# MDR_MLDR155 register map
Vendor: Milandr; Series: ARMCM4; File version: 2.0
CPU: CM4 r0p0, little endian, MPU, FPU, 3 interrupt priority bits
Registers are 32-bit, read-write, reset 0x0 unless marked. A register's access mark holds for its fields unless they carry their own. Offsets are from the block's base; [hi:lo] are bit positions; {n}, {i} and the like mark numbered series; 'fields as' and 'values as' point back to an identical list.

## MDR_RST_CLOCK — CLock Control
Base 0x40000000
0x00 KEY — Clock Unlock Register
  [31:0] Value — Reg value
0x04 MAX_CLK — MAX_CLK Select Register
  [3:0] Select — Select MAX_CLOCK source
    0=HSI (MAX_CLOCK is HSI); 1=HSI_div2 (MAX_CLOCK is HSI/2); 2=HSE0 (MAX_CLOCK is HSE0); 3=HSE0_div2 (MAX_CLOCK is HSE0/2); 4=HSE1 (MAX_CLOCK is HSE1); 5=HSE1_div2 (MAX_CLOCK is HSE1/2); 6=LSI (MAX_CLOCK is LSI); 7=LSE (MAX_CLOCK is LSE); {v}=PLL{v-8} (MAX_CLOCK is PLL{v-8}) (v=8..11)
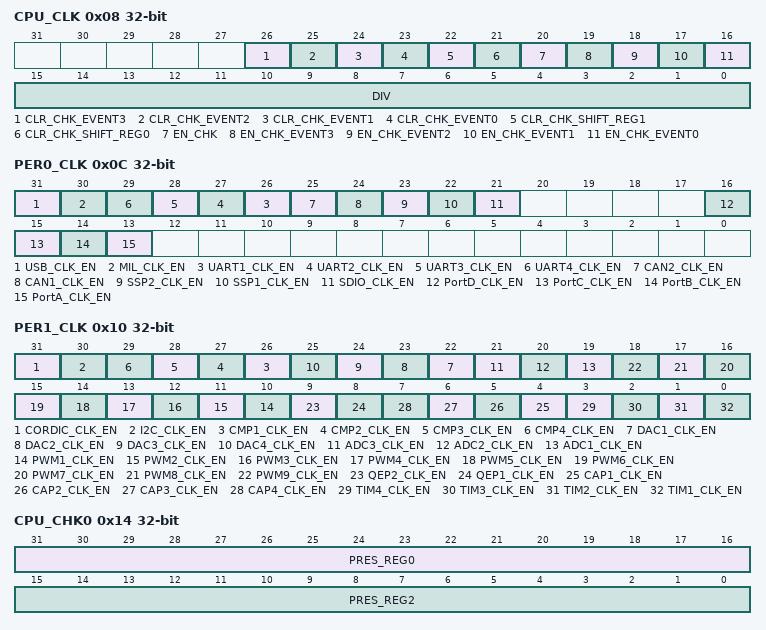
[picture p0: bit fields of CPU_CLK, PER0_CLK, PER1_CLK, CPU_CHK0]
0x08 CPU_CLK
  [26] CLR_CHK_EVENT3 — Clear highest freq event
    0=Inactive (No action); 1=Clear level
  [25] CLR_CHK_EVENT2 — Clear high freq event
    0=Inactive (No action); 1=Clear level
  [24] CLR_CHK_EVENT1 — Clear low freq event
    0=Inactive (No action); 1=Clear level
  [23] CLR_CHK_EVENT0 — Clear no freq event
    0=Inactive (No action); 1=Clear level
  [22] CLR_CHK_SHIFT_REG1 — Clear Max Freq level
    0=Inactive (No action); 1=Clear level
  [21] CLR_CHK_SHIFT_REG0 — Clear Min Freq level
    0=Inactive (No action); 1=Clear level
  [20] EN_CHK — Clock Checker enable
    0=Off (Disable); 1=On (Enable)
  [19] EN_CHK_EVENT3 — Go to HSI if active clock is Highest
    0=Off (Disable); 1=On (Enable)
  [18] EN_CHK_EVENT2 — Go to HSI if active clock is High
    0=Off (Disable); 1=On (Enable)
  [17] EN_CHK_EVENT1 — Go to HSI if active clock is low
    0=Off (Disable); 1=On (Enable)
  [16] EN_CHK_EVENT0 — Go to HSI on lose active clock
    0=Off (Disable); 1=On (Enable)
  [15:0] DIV — CPU_CLock div from MAX_CLOCK
0x0C PER0_CLK — Periph0 Clock Enable Register
  [all] fields
    0=Off (Disable); 1=On (Enable)
  [31] USB_CLK_EN — USB Clock Enable
  [30] MIL_CLK_EN — MIL Clock Enable
  [n+25] UART{n}_CLK_EN (n=1..4) — UART{n} Clock Enable
  [25] CAN2_CLK_EN — CAN2 Clock Enable
  [24] CAN1_CLK_EN — CAN1 Clock Enable
  [23] SSP2_CLK_EN — SSP2 Clock Enable
  [22] SSP1_CLK_EN — SSP1 Clock Enable
  [21] SDIO_CLK_EN — SDIO Clock Enable
  [16] PortD_CLK_EN — GPIO Port Clock Enable
  [15] PortC_CLK_EN — GPIO Port Clock Enable
  [14] PortB_CLK_EN — GPIO Port Clock Enable
  [13] PortA_CLK_EN — GPIO Port Clock Enable
0x10 PER1_CLK — Periph1 Clock Enable Register
  [all] fields
    0=Off (Disable); 1=On (Enable)
  [31] CORDIC_CLK_EN — CORDIC Clock Enable
  [30] I2C_CLK_EN — I2C Clock Enable
  [n+25] CMP{n}_CLK_EN (n=1..4) — Comparator{n} Clock Enable
  [n+21] DAC{n}_CLK_EN (n=1..4) — DAC{n} Clock Enable
  [21] ADC3_CLK_EN — ADC3 Clock Enable
  [20] ADC2_CLK_EN — ADC2 Clock Enable
  [19] ADC1_CLK_EN — ADC1 Clock Enable
  [n+9] PWM{n}_CLK_EN (n=1..9) — PWM{n} Clock Enable
  [9] QEP2_CLK_EN — Encoder2 Clock Enable
  [8] QEP1_CLK_EN — Encoder1 Clock Enable
  [n+3] CAP{n}_CLK_EN (n=1..4) — Capture{n} Clock Enable
  [3] TIM4_CLK_EN — Timer4 Clock Enable
  [2] TIM3_CLK_EN — Timer3 Clock Enable
  [1] TIM2_CLK_EN — Timer1 Clock Enable
  [0] TIM1_CLK_EN — Timer1 Clock Enable
0x14 CPU_CHK0 — Clock Checker Register
  [31:16] PRES_REG0 — FreqRef Prescaller for Fast
  [15:0] PRES_REG2 — FreqRef Prescaller for Slow
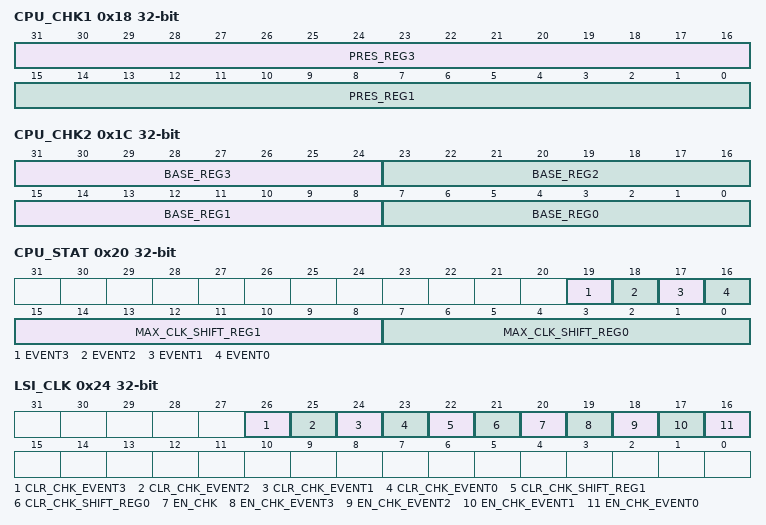
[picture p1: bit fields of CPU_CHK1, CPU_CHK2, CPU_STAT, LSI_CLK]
0x18 CPU_CHK1 — Clock Checker Register
  [31:16] PRES_REG3 — Clock Prescaller for Slow
  [15:0] PRES_REG1 — Clock Prescaller for Fast
0x1C CPU_CHK2 — Clock Checker Register
  [31:24] BASE_REG3 — Max factor for FASTEST
  [23:16] BASE_REG2 — Max factor for FAST
  [15:8] BASE_REG1 — Min factor for SLOW
  [7:0] BASE_REG0 — Min factor for SLOWEST
0x20 CPU_STAT — Clock Status Register
  [19] EVENT3 — Event FASTEST
    0=Off (Inactive); 1=On (Active)
  [18] EVENT2 — Event FAST
    0=Off (Inactive); 1=On (Active)
  [17] EVENT1 — Event SLOW
    0=Off (Inactive); 1=On (Active)
  [16] EVENT0 — Event SLOWEST
    0=Off (Inactive); 1=On (Active)
  [15:8] MAX_CLK_SHIFT_REG1 — Max factor detected for FAST
  [7:0] MAX_CLK_SHIFT_REG0 — Max factor detected for SLOW
0x24 LSI_CLK — Clock Contorl Register
  [26] CLR_CHK_EVENT3 — Clear highest freq event
    0=Inactive (No action); 1=Clear level
  [25] CLR_CHK_EVENT2 — Clear high freq event
    0=Inactive (No action); 1=Clear level
  [24] CLR_CHK_EVENT1 — Clear low freq event
    0=Inactive (No action); 1=Clear level
  [23] CLR_CHK_EVENT0 — Clear no freq event
    0=Inactive (No action); 1=Clear level
  [22] CLR_CHK_SHIFT_REG1 — Clear Max Freq level
    0=Inactive (No action); 1=Clear level
  [21] CLR_CHK_SHIFT_REG0 — Clear Min Freq level
    0=Inactive (No action); 1=Clear level
  [20] EN_CHK — Clock Checker enable
    0=Off (Disable); 1=On (Enable)
  [19] EN_CHK_EVENT3 — Go to HSI if active clock is Highest
    0=Off (Disable); 1=On (Enable)
  [18] EN_CHK_EVENT2 — Go to HSI if active clock is High
    0=Off (Disable); 1=On (Enable)
  [17] EN_CHK_EVENT1 — Go to HSI if active clock is low
    0=Off (Disable); 1=On (Enable)
  [16] EN_CHK_EVENT0 — Go to HSI on lose active clock
    0=Off (Disable); 1=On (Enable)
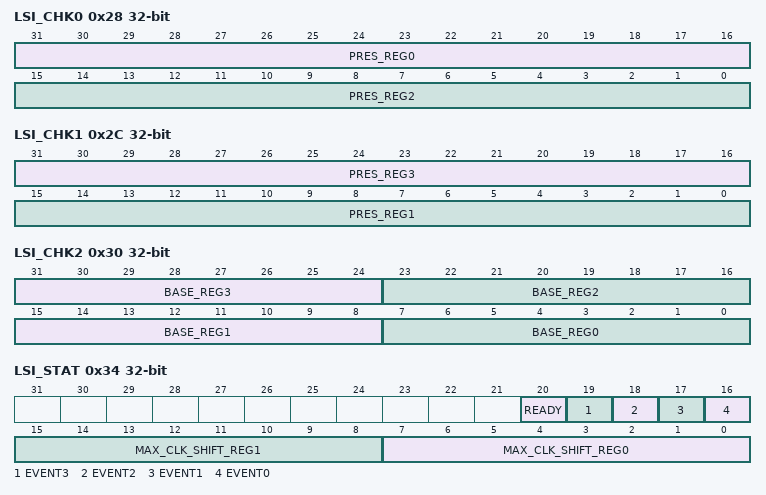
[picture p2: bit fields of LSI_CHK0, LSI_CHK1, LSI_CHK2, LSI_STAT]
0x28 LSI_CHK0 — Clock Checker Register
  fields as CPU_CHK0
0x2C LSI_CHK1 — Clock Checker Register
  fields as CPU_CHK1
0x30 LSI_CHK2 — Clock Checker Register
  fields as CPU_CHK2
0x34 LSI_STAT (reset mask 0xFFFFF) — Clock Status Register
  [20] READY — Clock Ready
    0=Off (Clock not Ready); 1=On (Clock Ready)
  [19] EVENT3 — Event FASTEST
    0=Off (Inactive); 1=On (Active)
  [18] EVENT2 — Event FAST
    0=Off (Inactive); 1=On (Active)
  [17] EVENT1 — Event SLOW
    0=Off (Inactive); 1=On (Active)
  [16] EVENT0 — Event SLOWEST
    0=Off (Inactive); 1=On (Active)
  [15:8] MAX_CLK_SHIFT_REG1 — Max factor detected for FAST
  [7:0] MAX_CLK_SHIFT_REG0 — Max factor detected for SLOW
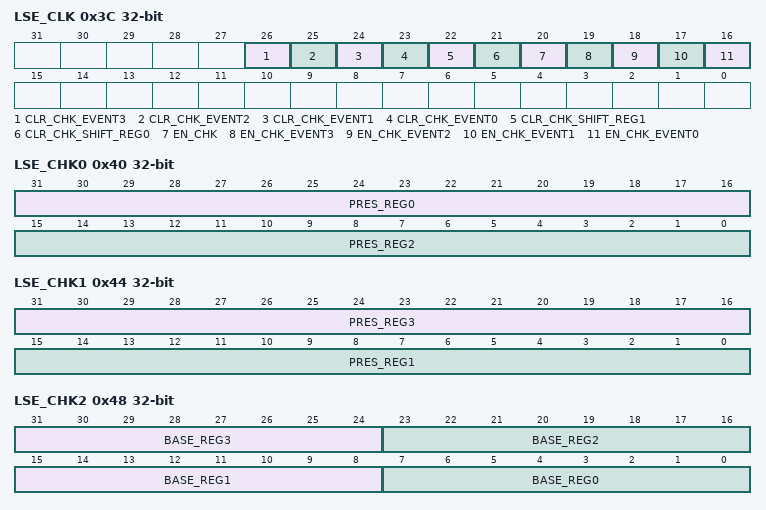
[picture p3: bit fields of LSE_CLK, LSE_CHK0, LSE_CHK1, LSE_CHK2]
0x3C LSE_CLK — Clock Contorl Register
  fields as LSI_CLK
0x40 LSE_CHK0 — Clock Checker Register
  fields as CPU_CHK0
0x44 LSE_CHK1 — Clock Checker Register
  fields as CPU_CHK1
0x48 LSE_CHK2 — Clock Checker Register
  fields as CPU_CHK2
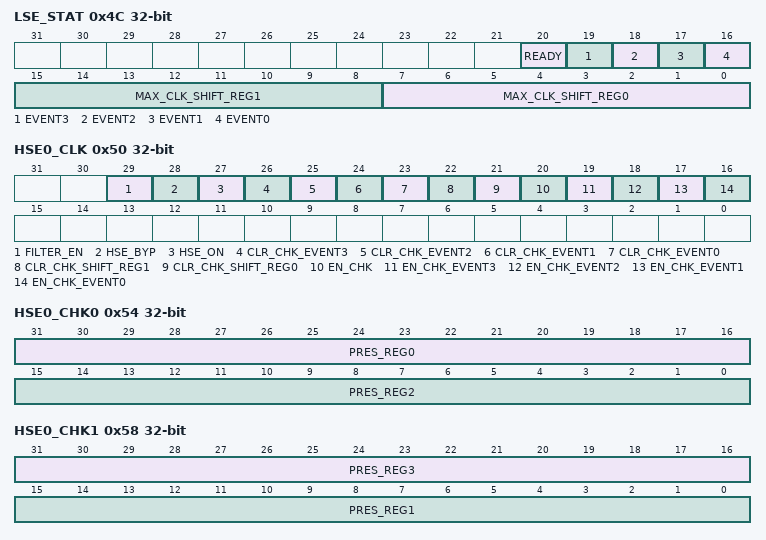
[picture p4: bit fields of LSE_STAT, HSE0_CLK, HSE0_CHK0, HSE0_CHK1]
0x4C LSE_STAT (reset mask 0xFFFFF) — Clock Status Register
  fields as LSI_STAT
0x50 HSE0_CLK (reset mask 0x7FF0000) — Clock Contorl Register
  [29] FILTER_EN — Filter Enable
    0=Off (Disable); 1=On (Enable)
  [28] HSE_BYP — ByPass Mode
    0=Off (Disable); 1=On (Enable)
  [27] HSE_ON — Generator Enable
    0=Off (Disable); 1=On (Enable)
  [26] CLR_CHK_EVENT3 — Clear highest freq event
    0=Inactive (No action); 1=Clear level
  [25] CLR_CHK_EVENT2 — Clear high freq event
    0=Inactive (No action); 1=Clear level
  [24] CLR_CHK_EVENT1 — Clear low freq event
    0=Inactive (No action); 1=Clear level
  [23] CLR_CHK_EVENT0 — Clear no freq event
    0=Inactive (No action); 1=Clear level
  [22] CLR_CHK_SHIFT_REG1 — Clear Max Freq level
    0=Inactive (No action); 1=Clear level
  [21] CLR_CHK_SHIFT_REG0 — Clear Min Freq level
    0=Inactive (No action); 1=Clear level
  [20] EN_CHK — Clock Checker enable
    0=Off (Disable); 1=On (Enable)
  [19] EN_CHK_EVENT3 — Go to HSI if active clock is Highest
    0=Off (Disable); 1=On (Enable)
  [18] EN_CHK_EVENT2 — Go to HSI if active clock is High
    0=Off (Disable); 1=On (Enable)
  [17] EN_CHK_EVENT1 — Go to HSI if active clock is low
    0=Off (Disable); 1=On (Enable)
  [16] EN_CHK_EVENT0 — Go to HSI on lose active clock
    0=Off (Disable); 1=On (Enable)
0x54 HSE0_CHK0 — Clock Checker Register
  fields as CPU_CHK0
0x58 HSE0_CHK1 — Clock Checker Register
  fields as CPU_CHK1
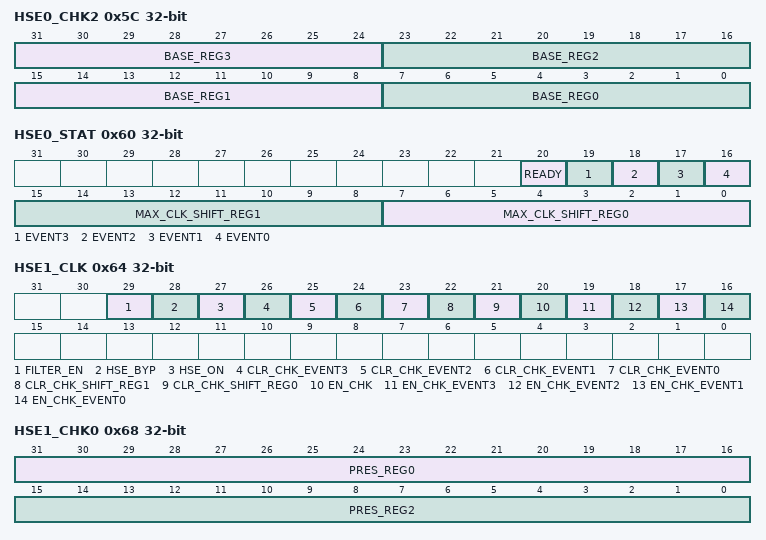
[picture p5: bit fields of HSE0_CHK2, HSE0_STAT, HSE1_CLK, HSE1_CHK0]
0x5C HSE0_CHK2 — Clock Checker Register
  fields as CPU_CHK2
0x60 HSE0_STAT (reset mask 0xFFFFF) — Clock Status Register
  fields as LSI_STAT
0x64 HSE1_CLK (reset mask 0x7FF0000) — Clock Contorl Register
  fields as HSE0_CLK
0x68 HSE1_CHK0 — Clock Checker Register
  fields as CPU_CHK0
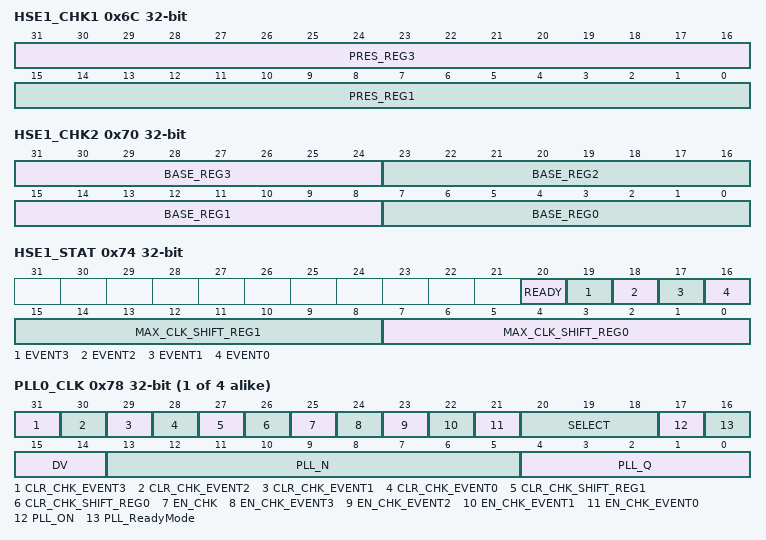
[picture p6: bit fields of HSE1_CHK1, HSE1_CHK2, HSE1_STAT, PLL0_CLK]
0x6C HSE1_CHK1 — Clock Checker Register
  fields as CPU_CHK1
0x70 HSE1_CHK2 — Clock Checker Register
  fields as CPU_CHK2
0x74 HSE1_STAT (reset mask 0xFFFFF) — Clock Status Register
  fields as LSI_STAT
{0x78+0x14*i} PLL{i}_CLK (i=0..3) — PLL0 Control
  [31] CLR_CHK_EVENT3 — Clear highest freq event
    0=Inactive (No action); 1=Clear level
  [30] CLR_CHK_EVENT2 — Clear high freq event
    0=Inactive (No action); 1=Clear level
  [29] CLR_CHK_EVENT1 — Clear low freq event
    0=Inactive (No action); 1=Clear level
  [28] CLR_CHK_EVENT0 — Clear no freq event
    0=Inactive (No action); 1=Clear level
  [27] CLR_CHK_SHIFT_REG1 — Clear Max Freq level
    0=Inactive (No action); 1=Clear level
  [26] CLR_CHK_SHIFT_REG0 — Clear Min Freq level
    0=Inactive (No action); 1=Clear level
  [25] EN_CHK — Clock Checker enable
    0=Off (Disable); 1=On (Enable)
  [24] EN_CHK_EVENT3 — Go to HSI if active clock is Highest
    0=Off (Disable); 1=On (Enable)
  [23] EN_CHK_EVENT2 — Go to HSI if active clock is High
    0=Off (Disable); 1=On (Enable)
  [22] EN_CHK_EVENT1 — Go to HSI if active clock is low
    0=Off (Disable); 1=On (Enable)
  [21] EN_CHK_EVENT0 — Go to HSI on lose active clock
    0=Off (Disable); 1=On (Enable)
  [20:18] SELECT — Select PLL Input
    0=HSI (HSI signal); 1=HSI_div2 (HSI/2 signal); 2=HSE0 (HSE0 signal); 3=HSE0_div2 (HSE0/2 signal); 4=HSE1 (HSE1 signal); 5=HSE1_div2 (HSE1/2 signal)
  [17] PLL_ON — PLL Enable
    0=Off (Disable); 1=On (Enable)
  [16] PLL_ReadyMode — Enable output after ready only
    0=Off (Disable); 1=On (Enable)
  [15:14] DV — PLL Output Divider
    0=div1 (Divider); 1=div2 (Divider); 2=div4 (Divider); 3=div8 (Divider)
  [13:5] PLL_N — PLL Freq multiplier
  [4:0] PLL_Q — PLL Freq divider
    {v}=div{v+1} (Divider) (v=0..31)
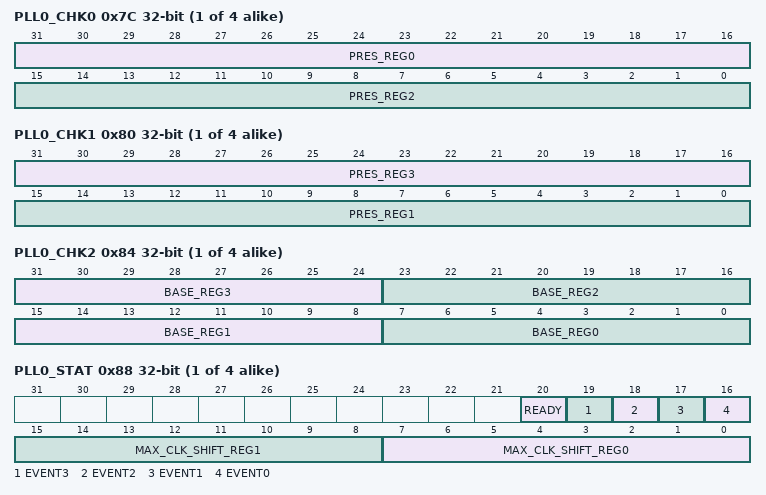
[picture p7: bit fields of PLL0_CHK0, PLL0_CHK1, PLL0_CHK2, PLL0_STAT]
{0x7C+0x14*i} PLL{i}_CHK0 (i=0..3) — Clock Checker Register
  fields as CPU_CHK0
{0x80+0x14*i} PLL{i}_CHK1 (i=0..3) — Clock Checker Register
  fields as CPU_CHK1
{0x84+0x14*i} PLL{i}_CHK2 (i=0..3) — Clock Checker Register
  fields as CPU_CHK2
{0x88+0x14*i} PLL{i}_STAT (reset mask 0xFFFFF) (i=0..3) — Clock Status Register
  fields as LSI_STAT
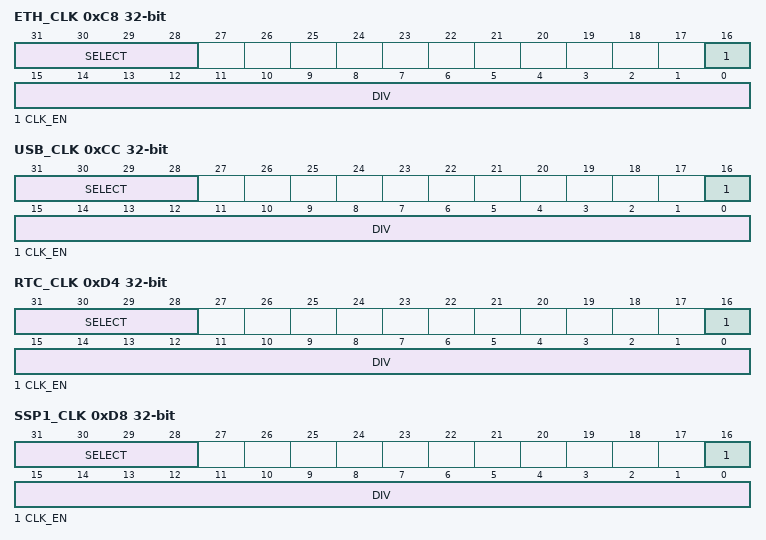
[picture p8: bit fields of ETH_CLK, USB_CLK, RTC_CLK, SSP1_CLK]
0xC8 ETH_CLK (reset mask 0xF001FFF) — Async Clock Control
  [31:28] SELECT — PeriphClock Enable
    0=HSI (Clock Source); 1=HSE0 (Clock Source); 2=HSE1 (Clock Source); 3=LSI (Clock Source); 4=LSE (Clock Source); 5=PLL0 (Clock Source); 6=PLL1 (Clock Source); 7=PLL2 (Clock Source); 13=MAX_CLK (Clock Source)
  [16] CLK_EN — PeriphClock Enable
    0=Off (Clock Off); 1=On (Clock On)
  [15:0] DIV — Div to PeriphClock
0xCC USB_CLK (reset mask 0xF001FFF) — Async Clock Control
  fields as ETH_CLK
0xD4 RTC_CLK (reset mask 0xF001FFF) — Async Clock Control
  fields as ETH_CLK
0xD8 SSP1_CLK (reset mask 0xF001FFF) — Async Clock Control
  fields as ETH_CLK
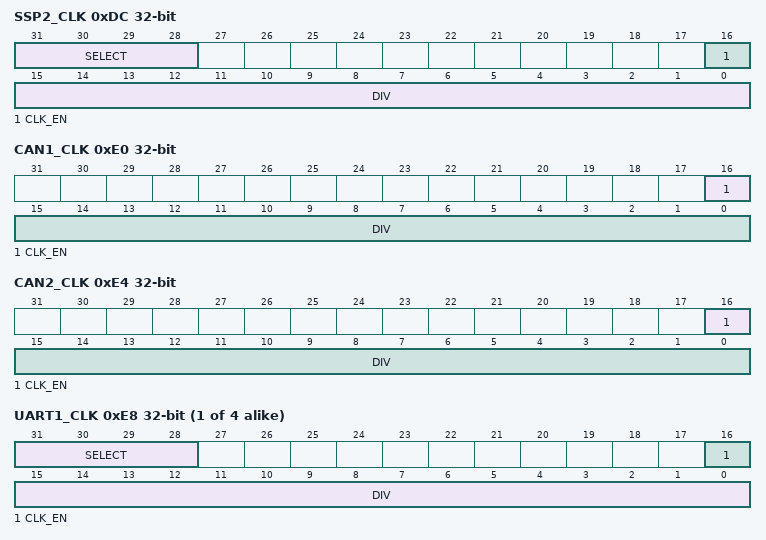
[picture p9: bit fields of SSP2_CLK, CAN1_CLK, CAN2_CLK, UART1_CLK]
0xDC SSP2_CLK (reset mask 0xF001FFF) — Async Clock Control
  fields as ETH_CLK
0xE0 CAN1_CLK (reset mask 0x1FFF) — Sync Clock Control
  [16] CLK_EN — PeriphClock Enable
    0=Off (Clock Off); 1=On (Clock On)
  [15:0] DIV — Div to PeriphClock
0xE4 CAN2_CLK (reset mask 0x1FFF) — Sync Clock Control
  fields as CAN1_CLK
{0xE4+4i} UART{i}_CLK (reset mask 0xF001FFF) (i=1..4) — Async Clock Control
  fields as ETH_CLK
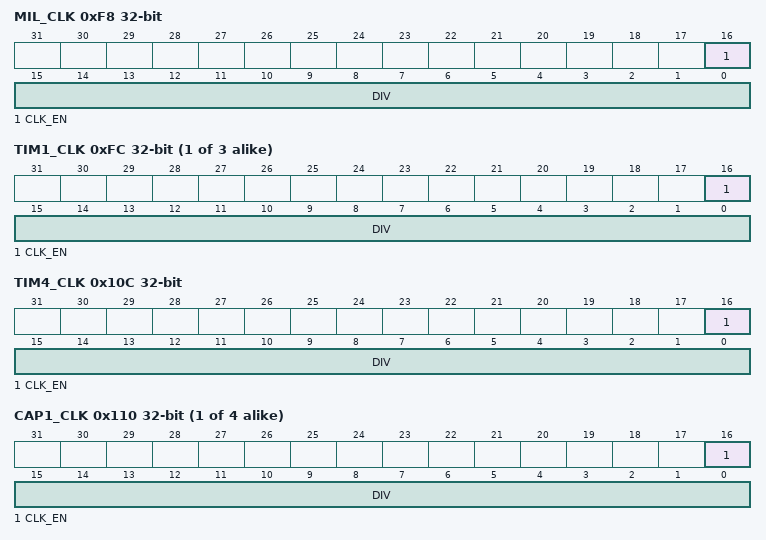
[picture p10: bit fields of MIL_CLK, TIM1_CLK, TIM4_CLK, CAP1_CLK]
0xF8 MIL_CLK (reset mask 0x1FFF) — Sync Clock Control
  fields as CAN1_CLK
{0xF8+4i} TIM{i}_CLK (reset mask 0x1FFF) (i=1..3) — Sync Clock Control
  fields as CAN1_CLK
0x10C TIM4_CLK (reset mask 0x1FFF) — Sync Clock Control
  fields as CAN1_CLK
{0x10C+4i} CAP{i}_CLK (reset mask 0x1FFF) (i=1..4) — Sync Clock Control
  fields as CAN1_CLK
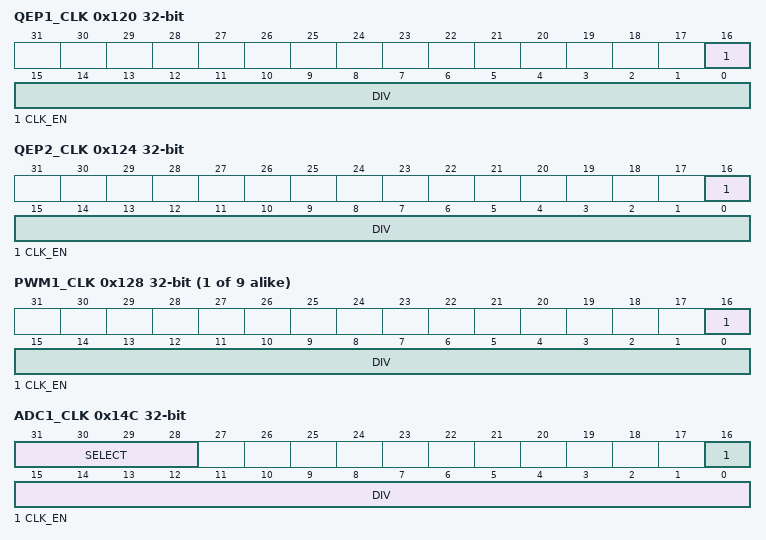
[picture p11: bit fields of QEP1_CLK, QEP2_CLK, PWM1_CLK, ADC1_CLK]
0x120 QEP1_CLK (reset mask 0x1FFF) — Sync Clock Control
  fields as CAN1_CLK
0x124 QEP2_CLK (reset mask 0x1FFF) — Sync Clock Control
  fields as CAN1_CLK
{0x124+4i} PWM{i}_CLK (reset mask 0x1FFF) (i=1..9) — Sync Clock Control
  fields as CAN1_CLK
0x14C ADC1_CLK (reset mask 0xF001FFF) — Async Clock Control
  fields as ETH_CLK
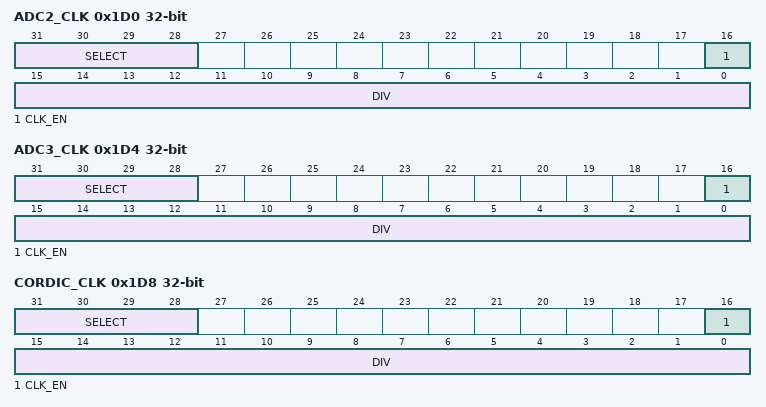
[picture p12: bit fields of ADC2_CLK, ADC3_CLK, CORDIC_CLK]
0x1D0 ADC2_CLK (reset mask 0xF001FFF) — Async Clock Control
  fields as ETH_CLK
0x1D4 ADC3_CLK (reset mask 0xF001FFF) — Async Clock Control
  fields as ETH_CLK
0x1D8 CORDIC_CLK (reset mask 0xF001FFF) — Async Clock Control
  fields as ETH_CLK
